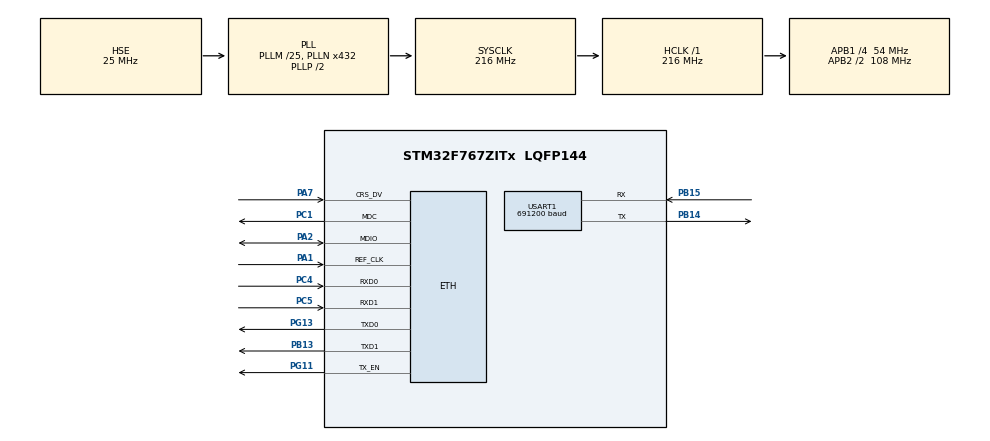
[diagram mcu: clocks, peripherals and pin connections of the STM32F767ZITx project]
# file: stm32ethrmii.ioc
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CORTEX_M7.AccessPermission_Spec=MPU_REGION_FULL_ACCESS
CORTEX_M7.BaseAddress_Spec=0x20020000
CORTEX_M7.CPU_DCache=Enabled
CORTEX_M7.CPU_ICache=Enabled
CORTEX_M7.PREFETCH_ENABLE=1
CORTEX_M7.Size_Spec=MPU_REGION_SIZE_32KB
CORTEX_M7.SubRegionDisable_Spec=0x0
CORTEX_M7.TypeExtField_Spec=MPU_TEX_LEVEL1
CORTEX_M7.default_mode_Activation=1
ETH.MediaInterface=HAL_ETH_RMII_MODE
ETH.RxDescAddress=0x20020000
ETH.TxDescAddress=0x20020160
LWIP.BSP.number=1
LWIP.GATEWAY_ADDRESS=192.168.001.254
LWIP.IP_ADDRESS=192.168.000.123
LWIP.LWIP_DHCP=0
LWIP.MEM_SIZE=10*1024
LWIP.NETMASK_ADDRESS=255.255.255.000
LWIP.Version=v2.1.2_Cube
LWIP0.BSP.STBoard=false
LWIP0.BSP.api=BSP_COMPONENT_DRIVER
LWIP0.BSP.component=LAN8742
LWIP0.BSP.instance=LAN8742
LWIP0.BSP.name=Driver_PHY
LWIP0.BSP.semaphore=S_LAN8742
LWIP0.BSP.solution=LAN8742
Mcu.Family=STM32F7
Mcu.Name=STM32F767ZITx
Mcu.Package=LQFP144
NVIC.ETH_IRQn=true\:0\:0\:true\:false\:true\:true\:true\:true
NVIC.PriorityGroup=NVIC_PRIORITYGROUP_4
NVIC.TIM1_UP_TIM10_IRQn=true\:3\:0\:true\:false\:true\:true\:true\:true
NVIC.USART1_IRQn=true\:0\:0\:false\:false\:true\:true\:true\:true
PA1.Mode=RMII
PA1.Signal=ETH_REF_CLK
PA2.Mode=RMII
PA2.Signal=ETH_MDIO
PA7.Mode=RMII
PA7.Signal=ETH_CRS_DV
PB13.Mode=RMII
PB13.Signal=ETH_TXD1
PB14.Mode=Asynchronous
PB14.Signal=USART1_TX
PB15.Mode=Asynchronous
PB15.Signal=USART1_RX
PC1.Mode=RMII
PC1.Signal=ETH_MDC
PC4.Mode=RMII
PC4.Signal=ETH_RXD0
PC5.Mode=RMII
PC5.Signal=ETH_RXD1
PD5.Signal=USART2_TX
PD6.Signal=USART2_RX
PG11.Mode=RMII
PG11.Signal=ETH_TX_EN
PG13.Mode=RMII
PG13.Signal=ETH_TXD0
PH0/OSC_IN.Mode=HSE-External-Oscillator
PH0/OSC_IN.Signal=RCC_OSC_IN
PH1/OSC_OUT.Mode=HSE-External-Oscillator
PH1/OSC_OUT.Signal=RCC_OSC_OUT
ProjectManager.HeapSize=0x200
ProjectManager.StackSize=0x400
ProjectManager.TargetToolchain=STM32CubeIDE
RCC.AHBFreq_Value=216000000
RCC.APB1CLKDivider=RCC_HCLK_DIV4
RCC.APB1Freq_Value=54000000
RCC.APB1TimFreq_Value=108000000
RCC.APB2CLKDivider=RCC_HCLK_DIV2
RCC.APB2Freq_Value=108000000
RCC.APB2TimFreq_Value=216000000
RCC.CortexFreq_Value=216000000
RCC.HCLKFreq_Value=216000000
RCC.HSE_VALUE=25000000
RCC.HSI_VALUE=16000000
RCC.LSE_VALUE=32768
RCC.PLLM=25
RCC.PLLN=432
RCC.PLLSourceVirtual=RCC_PLLSOURCE_HSE
RCC.SYSCLKFreq_VALUE=216000000
RCC.SYSCLKSource=RCC_SYSCLKSOURCE_PLLCLK
RCC.USART2CLockSelection=RCC_USART2CLKSOURCE_SYSCLK
RCC.USBFreq_Value=216000000
RCC.VCOOutputFreq_Value=432000000
TIM1.Period=10000-1
TIM1.Prescaler=10800-1
USART1.BaudRate=691200
USART1.VirtualMode-Asynchronous=VM_ASYNC
VP_LWIP_VS_Enabled.Mode=Enabled
VP_TIM1_VS_ClockSourceINT.Mode=Internal
board=custom

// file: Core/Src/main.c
/* USER CODE BEGIN Header */
/**
  ******************************************************************************
  * @file           : main.c
  * @brief          : Main program body
  ******************************************************************************
  * @attention
  *
  * Copyright (c) 2024 STMicroelectronics.
  * All rights reserved.
  *
  * This software is licensed under terms that can be found in the LICENSE file
  * in the root directory of this software component.
  * If no LICENSE file comes with this software, it is provided AS-IS.
  *
  ******************************************************************************
  */
/* USER CODE END Header */
#include "main.h"
#include "lwip.h"

/* USER CODE BEGIN PTD */
#define SIZE 1203
/* USER CODE END PTD */

/* USER CODE BEGIN PD */
//uint8_t data_buffer[SIZE*5];
uint8_t result_data[SIZE*5];
/* USER CODE END PD */

TIM_HandleTypeDef htim1;

UART_HandleTypeDef huart1;

void SystemClock_Config(void);
static void MPU_Config(void);
static void MX_GPIO_Init(void);
static void MX_TIM1_Init(void);
static void MX_USART1_UART_Init(void);
/* USER CODE BEGIN PFP */
extern  void udpClient_send(void);
/* USER CODE END PFP */

/* USER CODE BEGIN 0 */
extern struct netif gnetif;
/* USER CODE END 0 */

int main(void)
{

  /* MPU Configuration--------------------------------------------------------*/
  MPU_Config();

  /* Enable the CPU Cache */

  /* Enable I-Cache---------------------------------------------------------*/
  SCB_EnableICache();

  /* Enable D-Cache---------------------------------------------------------*/
  SCB_EnableDCache();

  /* MCU Configuration--------------------------------------------------------*/

  /* Reset of all peripherals, Initializes the Flash interface and the Systick. */
  HAL_Init();

  /* Configure the system clock */
  SystemClock_Config();

  /* Initialize all configured peripherals */
  MX_GPIO_Init();
  MX_LWIP_Init();
  MX_TIM1_Init();
  MX_USART1_UART_Init();
  /* USER CODE BEGIN 2 */
 HAL_TIM_Base_Start_IT(&htim1);
 //HAL_SPI_Receive_IT(&hspi1,result_data,SIZE*5);
  HAL_UART_Receive_IT(&huart1,result_data,SIZE*5);
  //HAL_UART_Receive_IT (&huart2,data_buffer, sizeof(data_buffer));
  udpClient_connect();
  /* USER CODE END 2 */

  /* Infinite loop */
  while (1)
  {
	  //ethernetif_input(&gnetif);
	  	  //sys_check_timeouts();
	  	  	HAL_UART_Receive_IT (&huart1,result_data, SIZE*5);
  }
}

void SystemClock_Config(void)
{
  RCC_OscInitTypeDef RCC_OscInitStruct = {0};
  RCC_ClkInitTypeDef RCC_ClkInitStruct = {0};

  /** Configure the main internal regulator output voltage
  */
  __HAL_RCC_PWR_CLK_ENABLE();
  __HAL_PWR_VOLTAGESCALING_CONFIG(PWR_REGULATOR_VOLTAGE_SCALE1);

  /** Initializes the RCC Oscillators according to the specified parameters
  * in the RCC_OscInitTypeDef structure.
  */
  RCC_OscInitStruct.OscillatorType = RCC_OSCILLATORTYPE_HSE;
  RCC_OscInitStruct.HSEState = RCC_HSE_ON;
  RCC_OscInitStruct.PLL.PLLState = RCC_PLL_ON;
  RCC_OscInitStruct.PLL.PLLSource = RCC_PLLSOURCE_HSE;
  RCC_OscInitStruct.PLL.PLLM = 25;
  RCC_OscInitStruct.PLL.PLLN = 432;
  RCC_OscInitStruct.PLL.PLLP = RCC_PLLP_DIV2;
  RCC_OscInitStruct.PLL.PLLQ = 2;
  RCC_OscInitStruct.PLL.PLLR = 2;
  if (HAL_RCC_OscConfig(&RCC_OscInitStruct) != HAL_OK)
  {
    Error_Handler();
  }

  /** Activate the Over-Drive mode
  */
  if (HAL_PWREx_EnableOverDrive() != HAL_OK)
  {
    Error_Handler();
  }

  /** Initializes the CPU, AHB and APB buses clocks
  */
  RCC_ClkInitStruct.ClockType = RCC_CLOCKTYPE_HCLK|RCC_CLOCKTYPE_SYSCLK
                              |RCC_CLOCKTYPE_PCLK1|RCC_CLOCKTYPE_PCLK2;
  RCC_ClkInitStruct.SYSCLKSource = RCC_SYSCLKSOURCE_PLLCLK;
  RCC_ClkInitStruct.AHBCLKDivider = RCC_SYSCLK_DIV1;
  RCC_ClkInitStruct.APB1CLKDivider = RCC_HCLK_DIV4;
  RCC_ClkInitStruct.APB2CLKDivider = RCC_HCLK_DIV2;

  if (HAL_RCC_ClockConfig(&RCC_ClkInitStruct, FLASH_LATENCY_7) != HAL_OK)
  {
    Error_Handler();
  }
}

static void MX_TIM1_Init(void)
{

  TIM_ClockConfigTypeDef sClockSourceConfig = {0};
  TIM_MasterConfigTypeDef sMasterConfig = {0};

  htim1.Instance = TIM1;
  htim1.Init.Prescaler = 10800-1;
  htim1.Init.CounterMode = TIM_COUNTERMODE_UP;
  htim1.Init.Period = 10000-1;
  htim1.Init.ClockDivision = TIM_CLOCKDIVISION_DIV1;
  htim1.Init.RepetitionCounter = 0;
  htim1.Init.AutoReloadPreload = TIM_AUTORELOAD_PRELOAD_DISABLE;
  if (HAL_TIM_Base_Init(&htim1) != HAL_OK)
  {
    Error_Handler();
  }
  sClockSourceConfig.ClockSource = TIM_CLOCKSOURCE_INTERNAL;
  if (HAL_TIM_ConfigClockSource(&htim1, &sClockSourceConfig) != HAL_OK)
  {
    Error_Handler();
  }
  sMasterConfig.MasterOutputTrigger = TIM_TRGO_RESET;
  sMasterConfig.MasterOutputTrigger2 = TIM_TRGO2_RESET;
  sMasterConfig.MasterSlaveMode = TIM_MASTERSLAVEMODE_DISABLE;
  if (HAL_TIMEx_MasterConfigSynchronization(&htim1, &sMasterConfig) != HAL_OK)
  {
    Error_Handler();
  }

}

static void MX_USART1_UART_Init(void)
{

  huart1.Instance = USART1;
  huart1.Init.BaudRate = 2764800;
  huart1.Init.WordLength = UART_WORDLENGTH_8B;
  huart1.Init.StopBits = UART_STOPBITS_1;
  huart1.Init.Parity = UART_PARITY_NONE;
  huart1.Init.Mode = UART_MODE_TX_RX;
  huart1.Init.HwFlowCtl = UART_HWCONTROL_NONE;
  huart1.Init.OverSampling = UART_OVERSAMPLING_16;
  huart1.Init.OneBitSampling = UART_ONE_BIT_SAMPLE_DISABLE;
  huart1.AdvancedInit.AdvFeatureInit = UART_ADVFEATURE_NO_INIT;
  if (HAL_UART_Init(&huart1) != HAL_OK)
  {
    Error_Handler();
  }

}

static void MX_GPIO_Init(void)
{
  GPIO_InitTypeDef GPIO_InitStruct = {0};

  /* GPIO Ports Clock Enable */
  __HAL_RCC_GPIOH_CLK_ENABLE();
  __HAL_RCC_GPIOC_CLK_ENABLE();
  __HAL_RCC_GPIOA_CLK_ENABLE();
  __HAL_RCC_GPIOB_CLK_ENABLE();
  __HAL_RCC_GPIOD_CLK_ENABLE();
  __HAL_RCC_GPIOG_CLK_ENABLE();

  /*Configure GPIO pins : PD5 PD6 */
  GPIO_InitStruct.Pin = GPIO_PIN_5|GPIO_PIN_6;
  GPIO_InitStruct.Mode = GPIO_MODE_AF_PP;
  GPIO_InitStruct.Pull = GPIO_NOPULL;
  GPIO_InitStruct.Speed = GPIO_SPEED_FREQ_VERY_HIGH;
  GPIO_InitStruct.Alternate = GPIO_AF7_USART2;
  HAL_GPIO_Init(GPIOD, &GPIO_InitStruct);

}

/* USER CODE BEGIN 4 */
void HAL_UART_RxCpltCallback(UART_HandleTypeDef *huart)
{

	HAL_UART_Receive_IT (&huart1,result_data, SIZE*5);

	/*if (data_buffer[1]==1 && data_buffer[0]==160 && data_buffer[1202]==254)  {
		memcpy(result_data,data_buffer,SIZE);
	}
	if (data_buffer[1]==2 && data_buffer[0]==160 && data_buffer[1202]==254) {
			memcpy(result_data+SIZE,data_buffer,SIZE);
		}
	if (data_buffer[1]==3 && data_buffer[0]==160 && data_buffer[1202]==254) {
			memcpy(result_data+2*SIZE,data_buffer,SIZE);
		}
	if (data_buffer[1]==4 && data_buffer[0]==160 && data_buffer[1202]==254) {
			memcpy(result_data+3*SIZE,data_buffer,SIZE);
		}
	if (data_buffer[1]==5 && data_buffer[0]==160 && data_buffer[1202]==254) {
			memcpy(result_data+4*SIZE,data_buffer,SIZE);
		}
*/
	//if(data_buffer[])

}

/* USER CODE END 4 */

 /* MPU Configuration */

void MPU_Config(void)
{
  MPU_Region_InitTypeDef MPU_InitStruct = {0};

  /* Disables the MPU */
  HAL_MPU_Disable();

  /** Initializes and configures the Region and the memory to be protected
  */
  MPU_InitStruct.Enable = MPU_REGION_ENABLE;
  MPU_InitStruct.Number = MPU_REGION_NUMBER0;
  MPU_InitStruct.BaseAddress = 0x20020000;
  MPU_InitStruct.Size = MPU_REGION_SIZE_32KB;
  MPU_InitStruct.SubRegionDisable = 0x0;
  MPU_InitStruct.TypeExtField = MPU_TEX_LEVEL1;
  MPU_InitStruct.AccessPermission = MPU_REGION_FULL_ACCESS;
  MPU_InitStruct.DisableExec = MPU_INSTRUCTION_ACCESS_DISABLE;
  MPU_InitStruct.IsShareable = MPU_ACCESS_SHAREABLE;
  MPU_InitStruct.IsCacheable = MPU_ACCESS_NOT_CACHEABLE;
  MPU_InitStruct.IsBufferable = MPU_ACCESS_NOT_BUFFERABLE;

  HAL_MPU_ConfigRegion(&MPU_InitStruct);
  /* Enables the MPU */
  HAL_MPU_Enable(MPU_PRIVILEGED_DEFAULT);

}

void Error_Handler(void)
{
  __disable_irq();
  while (1)
  {
  }
}
